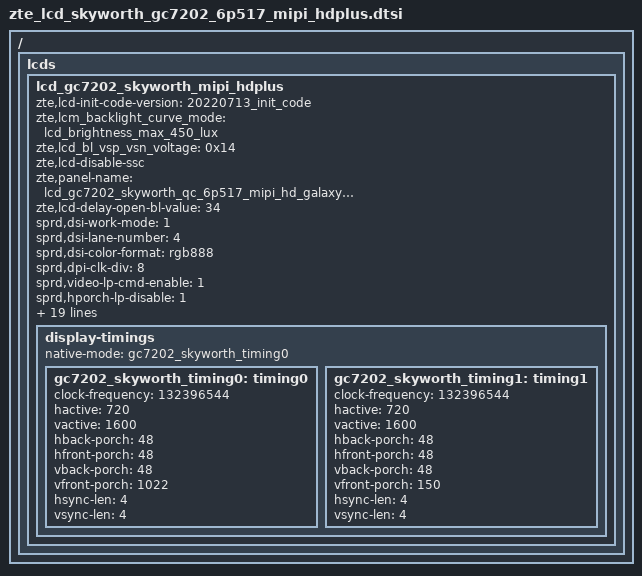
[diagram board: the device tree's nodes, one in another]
/ {
	fragment {
		target-path = "/";
		__overlay__ {
			lcds {
				lcd_gc7202_skyworth_mipi_hdplus: lcd_gc7202_skyworth_mipi_hdplus {
					zte,lcd-init-code-version = "20220713_init_code";

					zte,lcm_backlight_curve_mode = "lcd_brightness_max_450_lux";
					zte,lcd_bl_vsp_vsn_voltage = <0x14>;
					zte,lcd-disable-ssc;
					zte,panel-name = "lcd_gc7202_skyworth_qc_6p517_mipi_hd_galaxycore_4lane";
					zte,lcd-delay-open-bl-value = <34>;

					sprd,dsi-work-mode = <1>;
					sprd,dsi-lane-number = <4>;
					sprd,dsi-color-format = "rgb888";

					sprd,dpi-clk-div = <8>;
					sprd,video-lp-cmd-enable = <1>;
					sprd,hporch-lp-disable = <1>;

					sprd,phy-bit-clock = <1059173>;
					sprd,phy-escape-clock = <20000>;/* kHz */

					sprd,width-mm = <67932>;
					sprd,height-mm = <150960>;

					sprd,esd-check-enable = <1>;/* 0:close , 1:open */
					sprd,esd-check-mode = <1>;/* 0:REG ,1:TE  */
					sprd,esd-check-period = <2000>;

		sprd,reset-on-sequence = <1 10>, <0 10>, <1 35>, <0 10>, <1 10>, <0 10>, <1 10>, <0 10>, <1 30>;
		sprd,reset-off-sequence = <1 10>;
		sprd,use-dcs-write;
		sprd,initial-command = [
39 00 00 04 FF 55 AA 66
15 00 00 02 FF 20
15 00 00 02 FB 00
15 00 00 02 FF 21
15 00 00 02 FB 00
15 00 00 02 FF 22
15 00 00 02 FB 00
15 00 00 02 FF 23
15 00 00 02 FB 00
15 00 00 02 FF 24
15 00 00 02 FB 00
15 00 00 02 FF 26
15 00 00 02 FB 00
15 00 00 02 FF 27
15 00 00 02 FB 00
15 00 00 02 FF A3
15 00 00 02 FB 00
15 00 00 02 FF B3
15 00 00 02 FB 00
15 00 00 02 FF 22
15 00 00 02 08 40
15 00 00 02 FF 20
15 00 00 02 A5 00
15 00 00 02 A6 fF
15 00 00 02 A9 00
15 00 00 02 AA fF
15 00 00 02 AD 00
15 00 00 02 AE fF
15 00 00 02 B1 00
15 00 00 02 B2 fF
15 00 00 02 18 44
15 00 00 02 17 52
15 00 00 02 12 A2
15 00 00 02 15 4C
15 00 00 02 FF B3
15 00 00 02 82 1A
15 00 00 02 3F 3F
15 00 00 02 5E 10
15 00 00 02 58 84
15 00 00 02 FF 22
15 00 00 02 E4 01
15 00 00 02 01 06
15 00 00 02 02 40
15 00 00 02 25 08
15 00 00 02 26 00
15 00 00 02 2E AA
15 00 00 02 2F 00
15 00 00 02 36 09
15 00 00 02 37 00
15 00 00 02 3F aa
15 00 00 02 40 00
15 00 00 02 DC 00
/*15 00 00 02  E0 01 pwm out put*/
15 00 00 02 FF 20
15 00 00 02 C3 00
15 00 00 02 C4 6A
15 00 00 02 C5 00
15 00 00 02 C6 6A
15 00 00 02 B3 00
15 00 00 02 B4 28
15 00 00 02 B5 00
15 00 00 02 B6 C8
15 00 00 02 D3 1E
15 00 00 02 A3 49
15 00 00 02 A7 49
15 00 00 02 FF A3
15 00 00 02 FA 01
15 00 00 02 35 01
15 00 00 02 FF 26
39 00 00 05 1D 0C 00 00 00
15 00 00 02 FF 21
15 00 00 02 01 1A
15 00 00 02 02 1A
15 00 00 02 03 1E
15 00 00 02 04 02
15 00 00 02 05 04
15 00 00 02 06 1E
15 00 00 02 07 1E
15 00 00 02 08 20
15 00 00 02 09 21
15 00 00 02 0A 08
15 00 00 02 0B 0a
15 00 00 02 0C 0c
15 00 00 02 0D 0e
15 00 00 02 0E 10
15 00 00 02 0F 12
15 00 00 02 10 00
15 00 00 02 11 25
15 00 00 02 12 25
15 00 00 02 13 25
15 00 00 02 14 25
15 00 00 02 15 25
15 00 00 02 16 25
15 00 00 02 17 1A
15 00 00 02 18 1A
15 00 00 02 19 07
15 00 00 02 1A 03
15 00 00 02 1B 05
15 00 00 02 1C 07
15 00 00 02 1D 07
15 00 00 02 1E 20
15 00 00 02 1F 21
15 00 00 02 20 09
15 00 00 02 21 0B
15 00 00 02 22 0D
15 00 00 02 23 0F
15 00 00 02 24 11
15 00 00 02 25 13
15 00 00 02 26 01
15 00 00 02 27 25
15 00 00 02 28 25
15 00 00 02 29 25
15 00 00 02 2A 25
15 00 00 02 2B 25
15 00 00 02 2D 25
15 00 00 02 7E 07
15 00 00 02 7F 26
15 00 00 02 8B 26
15 00 00 02 97 26
15 00 00 02 AF 42
15 00 00 02 B0 42
15 00 00 02 B1 42
15 00 00 02 83 03
15 00 00 02 8F 03
15 00 00 02 9B 03
15 00 00 02 87 00
15 00 00 02 93 26
15 00 00 02 9F 26
15 00 00 02 82 70
15 00 00 02 8E 70
15 00 00 02 9A 70
15 00 00 02 2B 00
15 00 00 02 2E 00
15 00 00 02 88 B7
15 00 00 02 89 30
15 00 00 02 8A 33
15 00 00 02 94 B7
15 00 00 02 95 30
15 00 00 02 96 33
15 00 00 02 A0 B7
15 00 00 02 A1 30
15 00 00 02 A2 33
15 00 00 02 45 BF
15 00 00 02 46 76
15 00 00 02 4C 76
15 00 00 02 52 76
15 00 00 02 58 76
15 00 00 02 5E 76
15 00 00 02 64 76
15 00 00 02 70 76
15 00 00 02 80 06
15 00 00 02 8C 02
15 00 00 02 98 19
15 00 00 02 47 0B
15 00 00 02 4D 0A
15 00 00 02 53 2D
15 00 00 02 59 2C
15 00 00 02 5F 2B
15 00 00 02 65 2A
15 00 00 02 71 21
15 00 00 02 76 44
15 00 00 02 77 44
15 00 00 02 78 44
15 00 00 02 79 44
15 00 00 02 7A 44
15 00 00 02 7B 44
15 00 00 02 7D 44
15 00 00 02 49 54
15 00 00 02 4A 40
15 00 00 02 4F 54
15 00 00 02 50 40
15 00 00 02 55 48
15 00 00 02 56 34
15 00 00 02 5B 48
15 00 00 02 5C 34
15 00 00 02 61 48
15 00 00 02 62 34
15 00 00 02 67 48
15 00 00 02 68 34
15 00 00 02 73 04
15 00 00 02 74 04
15 00 00 02 84 51
15 00 00 02 90 51
15 00 00 02 9C 51
15 00 00 02 85 50
15 00 00 02 91 50
15 00 00 02 9D 50
15 00 00 02 CA 5f
15 00 00 02 CB 3C
15 00 00 02 CD 3C
15 00 00 02 CC 10
15 00 00 02 CE 10
15 00 00 02 CF 76
15 00 00 02 D0 72
15 00 00 02 C2 84
15 00 00 02 C6 46
15 00 00 02 B3 a0
15 00 00 02 B4 26
15 00 00 02 BC 42
15 00 00 02 81 59
15 00 00 02 8D 46
15 00 00 02 99 42
15 00 00 02 54 40
15 00 00 02 5A 40
15 00 00 02 60 40
15 00 00 02 66 40
15 00 00 02 6C 40
15 00 00 02 72 40
15 00 00 02 B6 40
15 00 00 02 FF 20
15 00 00 02 25 16
15 00 00 02 50 04
15 00 00 02 51 02
15 00 00 02 FF 20
15 00 00 02 2D 1F
15 00 00 02 02 4C
15 00 00 02 03 4C
15 00 00 02 04 54
15 00 00 02 05 54
15 00 00 02 0A 40
15 00 00 02 0B 40
15 00 00 02 0C 54
15 00 00 02 0D 54
15 00 00 02 77 99
15 00 00 02 78 9C
/*  1C 8a 
  1D 8a vcom */
15 00 00 02 7E 01
15 00 00 02 7F 00
15 00 00 02 80 01
15 00 00 02 81 00
15 00 00 02 82 00
15 00 00 02 83 04
15 00 00 02 84 04
15 00 00 02 85 01
15 00 00 02 86 BD
15 00 00 02 87 01
15 00 00 02 88 8B
15 00 00 02 8A 03
15 00 00 02 8B 03
15 00 00 02 FF 23
39 00 00 11 01 00 00 00 19 00 4f 00 71 00 89 00 9f 00 b4 00 C3
39 00 00 11 02 00 D3 01 04 01 29 01 61 01 8a 01 c8 01 fe 02 00
39 00 00 11 03 02 3a 02 82 02 b1 02 ee 03 16 03 48 03 58 03 69
39 00 00 0D 04 03 7C 03 91 03 a9 03 c7 03 eb 03 FF
39 00 00 11 05 00 00 00 19 00 4f 00 71 00 89 00 9f 00 b4 00 C3
39 00 00 11 06 00 D3 01 04 01 29 01 61 01 8a 01 c8 01 fe 02 00
39 00 00 11 07 02 3a 02 82 02 b1 02 ee 03 16 03 48 03 58 03 69
39 00 00 0D 08 03 7C 03 91 03 a9 03 c7 03 eb 03 FF
39 00 00 11 09 00 00 00 19 00 4f 00 71 00 89 00 9f 00 b4 00 C3
39 00 00 11 0A 00 D3 01 04 01 29 01 61 01 8a 01 c8 01 fe 02 00
39 00 00 11 0B 02 3a 02 82 02 b1 02 ee 03 16 03 48 03 58 03 69
39 00 00 0D 0C 03 7C 03 91 03 a9 03 c7 03 eb 03 FF
39 00 00 11 0D 00 00 00 19 00 4f 00 71 00 89 00 9f 00 b4 00 C3
39 00 00 11 0E 00 D3 01 04 01 29 01 61 01 8a 01 c8 01 fe 02 00
39 00 00 11 0F 02 3a 02 82 02 b1 02 ee 03 16 03 48 03 58 03 69
39 00 00 0D 10 03 7C 03 91 03 a9 03 c7 03 eb 03 FF
39 00 00 11 11 00 00 00 19 00 4f 00 71 00 89 00 9f 00 b4 00 C3
39 00 00 11 12 00 D3 01 04 01 29 01 61 01 8a 01 c8 01 fe 02 00
39 00 00 11 13 02 3a 02 82 02 b1 02 ee 03 16 03 48 03 58 03 69
39 00 00 0D 14 03 7C 03 91 03 a9 03 c7 03 eb 03 FF
39 00 00 11 15 00 00 00 19 00 4f 00 71 00 89 00 9f 00 b4 00 C3
39 00 00 11 16 00 D3 01 04 01 29 01 61 01 8a 01 c8 01 fe 02 00
39 00 00 11 17 02 3a 02 82 02 b1 02 ee 03 16 03 48 03 58 03 69
39 00 00 0D 18 03 7C 03 91 03 a9 03 c7 03 eb 03 FF
15 00 00 02 FF 10
15 00 00 02 36 08
15 00 00 02 69 00
15 00 00 02 35 00
15 00 00 02 FF 24
15 00 00 02 7D 55
39 00 00 04 FF 66 99 55
15 00 00 02 FF 10
05 87 00 01 11 
05 14 00 01 29
		];

		sprd,sleep-in-command = [
39 00 00 04 FF 55 AA 66
15 00 00 02 FF 20
15 00 00 02 4A 01
15 00 00 02 48 10
15 00 00 02 49 00
15 00 00 02 FF 21
15 00 00 02 D1 00
15 00 00 02 FF 10
05 32 00 01 28
05 78 00 01 10
39 00 00 04 FF 55 AA 66
15 00 00 02 FF 26
15 00 00 02 FB 00
39 00 00 05 1D A2 AA AA 0A
15 00 00 02 FF 10
15 00 00 02 FB 00
15 00 00 02 4F 01
			];
		sprd,sleep-out-command = [
			13 78 00 01 11
			13 64 00 01 29
			];
		zte,brightness-levels = [
			39 00 00 03 51 06 66
			];

					display-timings {
						native-mode = <&gc7202_skyworth_timing0>;
						gc7202_skyworth_timing0: timing0 {/*60hz*/
							clock-frequency = <132396544>;
							hactive = <720>;
 							vactive = <1600>;
 							hback-porch = <48>;
 							hfront-porch = <48>;
							vback-porch = <48>;
							vfront-porch = <1022>;
 							hsync-len = <4>;
 							vsync-len = <4>;
 
 						};
						 gc7202_skyworth_timing1: timing1 {/*90hz*/
							clock-frequency = <132396544>;
 							hactive = <720>;
 							vactive = <1600>;
 							hback-porch = <48>;
 							hfront-porch = <48>;
							vback-porch = <48>;
							vfront-porch = <150>;
 							hsync-len = <4>;
 							vsync-len = <4>;
 
						};
					};
					/*
					oled-backlight {
						default-brightness-level = <1632>;
						sprd,max-level = <4095>;
						brightness-levels = [
							39 00 00 03 51 00 00
							39 00 00 02 53 2C
						];
					};*/
				};
			};
		};
	};
};
